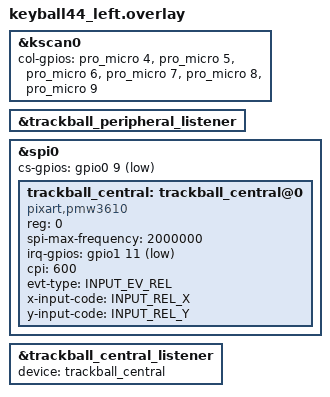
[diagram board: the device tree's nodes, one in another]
/*
 * Copyright (c) 2020 ZMK Contributors
 *
 * SPDX-License-Identifier: MIT
 */

#include "keyball44.dtsi"

&kscan0 {
	col-gpios
		= <&pro_micro 4 GPIO_ACTIVE_HIGH>
		, <&pro_micro 5 GPIO_ACTIVE_HIGH>
		, <&pro_micro 6 GPIO_ACTIVE_HIGH>
		, <&pro_micro 7 GPIO_ACTIVE_HIGH>
		, <&pro_micro 8 GPIO_ACTIVE_HIGH>
		, <&pro_micro 9 GPIO_ACTIVE_HIGH>
		;
};


&trackball_peripheral_listener {
    status = "okay";
};

#include <zephyr/dt-bindings/input/input-event-codes.h>
&spi0 {
    cs-gpios = <&gpio0 9 GPIO_ACTIVE_LOW>;

    trackball_central: trackball_central@0 {
        status = "okay";
        compatible = "pixart,pmw3610";
        reg = <0>;
        spi-max-frequency = <2000000>;
        irq-gpios = <&gpio1 11 (GPIO_ACTIVE_LOW | GPIO_PULL_UP)>;
        cpi = <600>;
        evt-type = <INPUT_EV_REL>;
        x-input-code = <INPUT_REL_X>;
        y-input-code = <INPUT_REL_Y>;
    };
};

// Overrides for the input listener node
&trackball_central_listener {
    status = "okay";
    device = <&trackball_central>;
};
